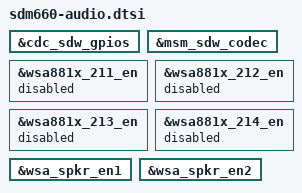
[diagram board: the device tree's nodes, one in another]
/*
 * Copyright (c) 2015-2017, The Linux Foundation. All rights reserved.
 * Copyright (C) 2019 XiaoMi, Inc.
 *
 * This program is free software; you can redistribute it and/or modify
 * it under the terms of the GNU General Public License version 2 and
 * only version 2 as published by the Free Software Foundation.
 *
 * This program is distributed in the hope that it will be useful,
 * but WITHOUT ANY WARRANTY; without even the implied warranty of
 * MERCHANTABILITY or FITNESS FOR A PARTICULAR PURPOSE.  See the
 * GNU General Public License for more details.
 */

/delete-node/ &wcd_usbc_analog_en1_gpio;
/delete-node/ &wcd_usbc_analog_en2n_gpio;

&cdc_sdw_gpios {
	/delete-property/ pinctrl-names;
	/delete-property/ pinctrl-0;
	/delete-property/ pinctrl-1;
};

&msm_sdw_codec {
	/delete-property/ qcom,cdc-sdw-gpios;
};

&wsa881x_211_en {
	status = "disabled";
};

&wsa881x_212_en {
	status = "disabled";
};

&wsa881x_213_en {
	status = "disabled";
};

&wsa881x_214_en {
	status = "disabled";
};

&wsa_spkr_en1 {
	/delete-property/ pinctrl-names;
	/delete-property/ pinctrl-0;
	/delete-property/ pinctrl-1;
};

&wsa_spkr_en2 {
	/delete-property/ pinctrl-names;
	/delete-property/ pinctrl-0;
	/delete-property/ pinctrl-1;
};
